# VIP1_Slice0_parser register map
Vendor: Texas Instruments
Peripheral module from a debugger description file (folder DRA75x_DRA74x).
Registers are 32-bit, read-only, reset 0x0 unless marked. A register's access mark holds for its fields unless they carry their own. Offsets are as the file gives them; lines under a group give offsets from that group; [hi:lo] are bit positions; {n}, {i} and the like mark numbered series; 'fields as' and 'values as' point back to an identical list; <NAME> marks a mode.

## VIP1_Slice0_parser
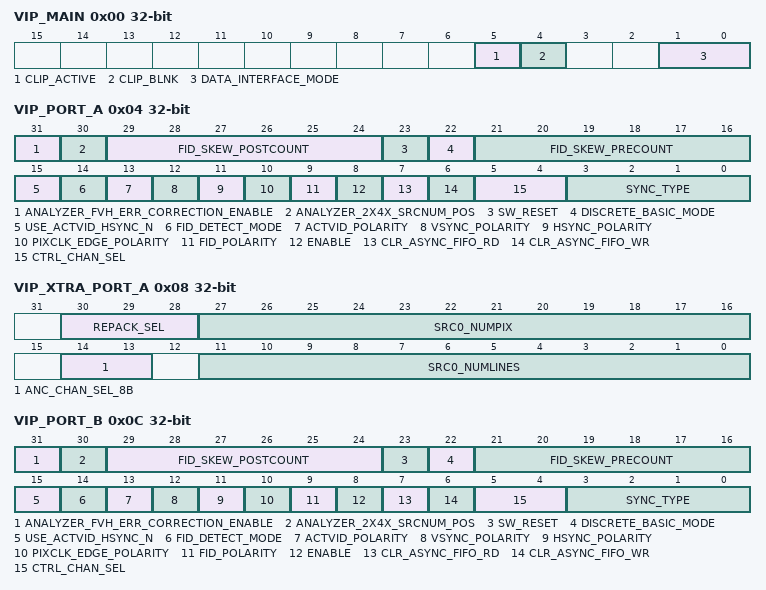
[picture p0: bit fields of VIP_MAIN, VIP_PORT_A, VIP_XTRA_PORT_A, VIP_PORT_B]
0x00 VIP_MAIN access per field — ain Configuration for VIP Parser
  [5] CLIP_ACTIVE rw — Discrete Sync Only 0 = Do not clip active pixels 1 = Clip Active Pixels as follows: 0xFF -andgt; 0xFE.. 0x00 -andgt; 0x01
  [4] CLIP_BLNK rw — Discrete Sync Only 0 = Do not clip Blanking Data 1 = Clip Blanking Data as follows: 0xFF -andgt; 0xFE.. 0x00 -andgt; 0x01
  [1:0] DATA_INTERFACE_MODE rw — 00 = 24b data interface. Uses Port A settings 01 = 16b data interface. Uses Port A settings. 10 = Dual independent 8b data interfaces. Uses independent Port A and Port B settings. 11 = Undefined
0x04 VIP_PORT_A rw — Configuration for Input Port A
  [31] ANALYZER_FVH_ERR_CORRECTION_ENABLE — Embedded Sync Only 0 = Ignore the protection bits in the XV (fvh) codeword header. This setting is typically desired. 1 = Use the protection bits in an attempt to do error correction for the fvh control bits.
  [30] ANALYZER_2X4X_SRCNUM_POS — Embedded Sync Only 0 = For 2x/4x mux mode, srcnum is in the least significant nibble of the XV/fvh codeword (srcnum replaces the protection bits) 1 = For 2x/4x mux mode, srcnum is in the least significant nibble of a horizontal blanking pixel value
  [29:24] FID_SKEW_POSTCOUNT — Discrete Sync Only post count value when using vsync skew in FID determination
  [23] SW_RESET — 0 = Normal 1 = Reset Port A logic. Must be set to ?0? again by the software for the module to function.
  [22] DISCRETE_BASIC_MODE — This register is valid for Discrete Sync mode only. 0 = Normal Discrete Mode. Hsync Style Capture operates as follows: - Captures line starting from HSYNC inactive to active condition. - VSYNC determined by sync window. - FID can be determined by VSYNC skew or captured from pin at first pixel in first line. ACTVID style capture works as follows: - Captures line during contiguous ACTVID envelope. - VSYNC is captured at the first pixel in each line. - FID is captured on first pixel of ACTVID window. 1 = Basic Discrete Mode. When using hsync with Hsync Style Capture operates as follows: - The last line of active video ends on the pixel clock cycle where VSYNC transitions from inactive to active. - FID pin value is captured on this cycle and is used for the next field. - FID detection by VSYNC skew is not allowed. ACTVID style capture works as follows: - VSYNC is expected to transition from inactive to active between ACTVID window. - This VSYNC transition allows the next line in an ACTVID envelope to be sent to a new VPDMA buffer. - FID value is determined by the FID pin value on the cycle where VSYNC transitions from inactive to active. In basic discrete mode, there is no Vertical Ancillary Data. Therefore, VPDMA descriptors should not use Ancillary Data channels.
  [21:16] FID_SKEW_PRECOUNT — Discrete Sync Only pre count value when using vsync skew in FID determination
  [15] USE_ACTVID_HSYNC_N — Discrete Sync Only 0 = Use HSYNC style line capture 1 = Use ACTVID style line capture
  [14] FID_DETECT_MODE — Discrete Sync Only 0 = Take FID from pin 1 = FID is determined by VSYNC skew
  [13] ACTVID_POLARITY — Discrete Sync Only 0 = ACTVID is active low 1 = ACTVID is active high
  [12] VSYNC_POLARITY — Discrete Sync Only 0 = VSYNC is active low 1 = VSYNC is active high
  [11] HSYNC_POLARITY — Discrete Sync Only 0 = HSYNC is active low 1 = HSYNC is active high
  [10] PIXCLK_EDGE_POLARITY — 0 = Rising Edge is active PIXCLK edge 1 = Falling Edge is active PIXCLK edge
  [9] FID_POLARITY — 0 = Keep FID as found 1 = Invert Determined Value of FID
  [8] ENABLE — 0 = Disable Port 1 = Enable Port
  [7] CLR_ASYNC_FIFO_RD — 0 = Normal 1 = Clear Async FIFO Read Logic
  [6] CLR_ASYNC_FIFO_WR — 0 = Normal 1 = Clear Async FIFO Write Logic
  [5:4] CTRL_CHAN_SEL — Embedded Sync Only In 8b mode.. there is only one channel on data[7:0]. In 16b mode.. there are two channels. The Luma Channel is on data[15:8]. The Chroma Channel is on data[7:0]. In 24b mode.. there are three channels. The R channel is on data[23:16].. the G channel is on [15:8]. and the B channel is on data[7:0]. 00 = Use data[7:0] to extract control codes. 01 = Use data[15:8] to extract control codes. 10 = Use data[23:16] to extract control codes. 11 = Undefined In 16b and 24b modes.. this register is also used to select the channel from which Ancillary Data is extracted. The Ancillary Data channel must be the same as the control code channel. For 8b mode.. the anc_chan_sel_8b register is used to select the Luma or Chroma channel from which Ancillary Data is taken.
  [3:0] SYNC_TYPE — 0000 = embedded sync single 4:2:2 YUV stream 0001 = embedded sync 2x multiplexed 4:2:2 YUV stream 0010 = embedded sync 4x multiplexed 4:2:2 YUV stream 0011 = embedded sync line multiplexed 4:2:2 YUV stream 0100 = discrete sync single 4:2:2 YUV stream 0101 = embedded sync single RGB stream or single 444 YUV stream 0110 = reserved 0111 = reserved 1000 = reserved 1001 = reserved 1010 = discrete sync single 24b RGB stream
0x08 VIP_XTRA_PORT_A access per field — ore Configuration for Input Port A
  [30:28] REPACK_SEL rw — 000 = Straight Through 001 = Cross Swap 010 = Left Center Swap 011 = Center Right Swap 100 = Right Rotate 101 = Left Rotate 110 = RAW16 to RGB565 Mapping 111 = RAW12 Swap
  [27:16] SRC0_NUMPIX rw — Number of expected pixels on Source Number 0. The Port_a_src0_size interrupt will trigger if a line is encountered that differs from this pixelcount.
  [14:13] ANC_CHAN_SEL_8B rw — In 8b mode, Vertically Ancillary Data typically resides in the Luma sites. This bit allows vertical ancillary data to be extracted from the chroma sites instead . 00 = Extract 8b Mode Vertical Ancillary Data from Luma Sites 01 = Extract 8b Mode Vertical Ancillary Data from Chroma Sites 10, 11 = Extract every single sample of vertical ancillary data. The output line is twice as wide as the other modes. For 16b and 24b inputs, ctrl_chan_sel is used to select which channel is used as a source for vertical ancillary data.
  [11:0] SRC0_NUMLINES rw — Number of expected lines on Source Number 0. The Port_a_src0_size interrupt will trigger if a field/frame is encountered that differs from this linecount.
0x0C VIP_PORT_B rw — Configuration for Input Port B
  [31] ANALYZER_FVH_ERR_CORRECTION_ENABLE — Embedded Sync Only 0 = Ignore the protection bits in the XV (fvh) codeword header. This setting is typically desired. 1 = Use the protection bits in an attempt to do error correction for the fvh control bits.
  [30] ANALYZER_2X4X_SRCNUM_POS — Embedded Sync Only 0 = For 2x/4x mux mode, srcnum is in the least significant nibble of the XV/fvh codeword (srcnum replaces the protection bits) 1 = For 2x/4x mux mode, srcnum is in the least significant nibble of a horizontal blanking pixel value
  [29:24] FID_SKEW_POSTCOUNT — Discrete Sync Only post count value when using vsync skew in FID determination
  [23] SW_RESET — 0 = Normal 1 = Reset Port B logic. Must be set to ?0? again by the software for the module to function.
  [22] DISCRETE_BASIC_MODE — This register is valid for Discrete Sync mode only. 0 = Normal Discrete Mode. Hsync Style Capture operates as follows: - Captures line starting from HSYNC inactive to active condition. - VSYNC determined by sync window. - FID can be determined by VSYNC skew or captured from pin at first pixel in first line. ACTVID style capture works as follows: - Captures line during contiguous ACTVID envelope. - VSYNC is captured at the first pixel in each line. - FID is captured on first pixel of ACTVID window. 1 = Basic Discrete Mode. When using hsync with Hsync Style Capture operates as follows: - The last line of active video ends on the pixel clock cycle where VSYNC transitions from inactive to active. - FID pin value is captured on this cycle and is used for the next field. - FID detection by VSYNC skew is not allowed. ACTVID style capture works as follows: - VSYNC is expected to transition from inactive to active between ACTVID window. - This VSYNC transition allows the next line in an ACTVID envelope to be sent to a new VPDMA buffer. - FID value is determined by the FID pin value on the cycle where VSYNC transitions from inactive to active. In basic discrete mode, there is no Vertical Ancillary Data. Therefore, VPDMA descriptors should not use Ancillary Data channels.
  [21:16] FID_SKEW_PRECOUNT — Discrete Sync Only pre count value when using vsync skew in FID determination
  [15] USE_ACTVID_HSYNC_N — Discrete Sync Only 0 = Use HSYNC style line capture 1 = Use ACTVID style line capture
  [14] FID_DETECT_MODE — Discrete Sync Only 0 = Take FID from pin 1 = FID is determined by VSYNC skew
  [13] ACTVID_POLARITY — Discrete Sync Only 0 = ACTVID is active low 1 = ACTVID is active high
  [12] VSYNC_POLARITY — Discrete Sync Only 0 = VSYNC is active low 1 = VSYNC is active high
  [11] HSYNC_POLARITY — Discrete Sync Only 0 = HSYNC is active low 1 = HSYNC is active high
  [10] PIXCLK_EDGE_POLARITY — 0 = Rising Edge is active PIXCLK edge 1 = Falling Edge is active PIXCLK edge
  [9] FID_POLARITY — 0 = Keep FID as found 1 = Invert Determined Value of FID
  [8] ENABLE — 0 = Disable 1 = Enable
  [7] CLR_ASYNC_FIFO_RD — 0 = Normal 1 = Clear Async FIFO Read Logic
  [6] CLR_ASYNC_FIFO_WR — 0 = Normal 1 = Clear Async FIFO Write Logic
  [5:4] CTRL_CHAN_SEL — PORT B supports on 8b mode. Always write 0 to this field. The anc_chan_sel_8b register is used to select the Luma or Chroma channel from which Ancillary Data is taken.
  [3:0] SYNC_TYPE — 0000 = embedded sync single YUV stream 0001 = embedded sync 2x multiplexed YUV stream 0010 = embedded sync 4x multiplexed YUV stream 0011 = embedded sync line multiplexed YUV stream 0100 = discrete sync single YUV stream 0101 = embedded sync single RGB stream 0110 = reserved 0111 = reserved 1000 = reserved 1001 = reserved 1010 = discrete sync single 24b RGB stream
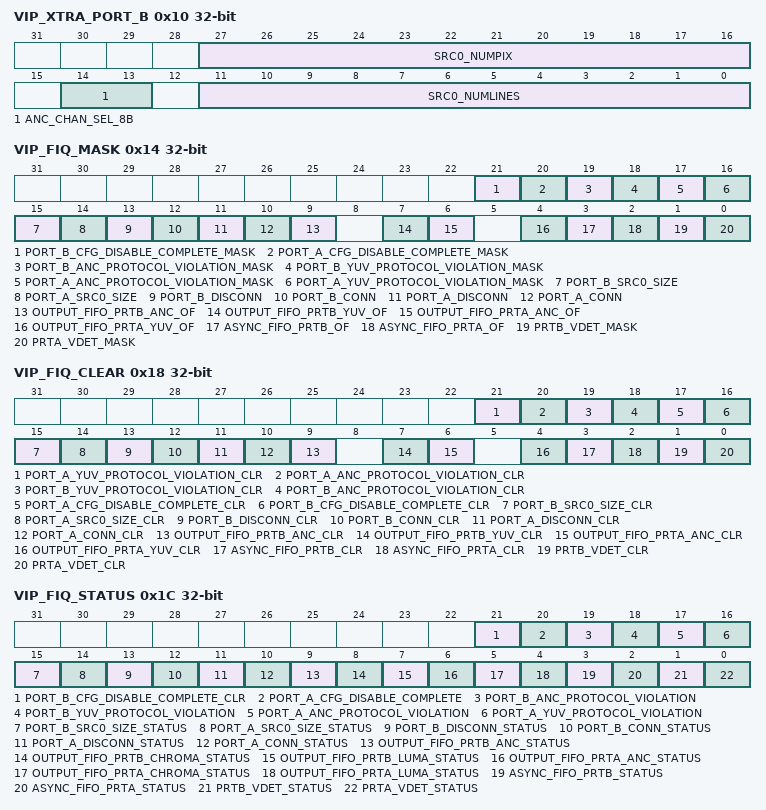
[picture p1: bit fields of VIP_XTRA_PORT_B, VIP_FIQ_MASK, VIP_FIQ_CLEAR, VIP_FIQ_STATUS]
0x10 VIP_XTRA_PORT_B access per field — ore Configuration for Input Port B
  [27:16] SRC0_NUMPIX rw — Number of expected pixels on Source Number 0. The Port_b_src0_size interrupt will trigger if a line is encountered that differs from this pixelcount.
  [14:13] ANC_CHAN_SEL_8B rw — In 8b mode, Vertically Ancillary Data typically resides in the Luma sites. This bit allows vertical ancillary data to be extracted from the chroma sites instead . 00 = Extract 8b Mode Vertical Ancillary Data from Luma Sites 01 = Extract 8b Mode Vertical Ancillary Data from Chroma Sites 10, 11 = Extract every single sample of vertical ancillary data. The output line is twice as wide as the other modes. For 16b and 24b inputs, ctrl_chan_sel is used to select which channel is used as a source for vertical ancillary data.
  [11:0] SRC0_NUMLINES rw — Number of expected lines on Source Number 0. The Port_b_src0_size interrupt will trigger if a field/frame is encountered that differs from this linecount.
0x14 VIP_FIQ_MASK access per field — ask Bits for ARM FIQs
  [21] PORT_B_CFG_DISABLE_COMPLETE_MASK rw
  [20] PORT_A_CFG_DISABLE_COMPLETE_MASK rw
  [19] PORT_B_ANC_PROTOCOL_VIOLATION_MASK rw — Port B ANC VPI Protocol Violation Mask
  [18] PORT_B_YUV_PROTOCOL_VIOLATION_MASK rw — Port B YUV VPI Protocol Violation Mask
  [17] PORT_A_ANC_PROTOCOL_VIOLATION_MASK rw — Port A ANC VPI Protocol Violation Mask
  [16] PORT_A_YUV_PROTOCOL_VIOLATION_MASK rw — Port A YUV VPI Protocol Violation Mask
  [15] PORT_B_SRC0_SIZE rw — Video size detected on Port B does not match size programmed in xtra_port_b register
  [14] PORT_A_SRC0_SIZE rw — Video size detected on Port A does not match size programmed in xtra_port_a register
  [13] PORT_B_DISCONN rw — Port B Link Disconnect Srcnum 0 Mask
  [12] PORT_B_CONN rw — Port B Link Connect Srcnum 0 Mask
  [11] PORT_A_DISCONN rw — Port A Link Disconnect Scrnum 0 Mask
  [10] PORT_A_CONN rw — Port A Link Connect Srcnum 0 Mask
  [9] OUTPUT_FIFO_PRTB_ANC_OF rw — Output FIFO Port B Ancillary Overflow Mask
  [7] OUTPUT_FIFO_PRTB_YUV_OF rw — Output FIFO Port B Luma Overflow Mask
  [6] OUTPUT_FIFO_PRTA_ANC_OF rw — Output FIFO Port A Ancillary Overflow Mask
  [4] OUTPUT_FIFO_PRTA_YUV_OF rw — Output FIFO Port A Luma Overflow Mask
  [3] ASYNC_FIFO_PRTB_OF rw — Port B Async FIFO Overflow FIQ Mask
  [2] ASYNC_FIFO_PRTA_OF rw — Port A Async FIFO Overflow FIQ Mask
  [1] PRTB_VDET_MASK rw — Port B Video Detect FIQ Mask
  [0] PRTA_VDET_MASK rw — Port A Video Detect FIQ Mask
0x18 VIP_FIQ_CLEAR access per field — Clears bits in the FIQ Status
  [21] PORT_A_YUV_PROTOCOL_VIOLATION_CLR rw — Write 1 followed by 0 to Clear Port B Cfg Disable Complete FIQ
  [20] PORT_A_ANC_PROTOCOL_VIOLATION_CLR rw — Write 1 followed by 0 to Clear Port A Cfg Disable Complete FIQ
  [19] PORT_B_YUV_PROTOCOL_VIOLATION_CLR rw — Write 1 followed by 0 to Clear Port B ANC VPI Protocol Violation FIQ
  [18] PORT_B_ANC_PROTOCOL_VIOLATION_CLR rw — Write 1 followed by 0 to Clear Port B YUV VPI Protocol Violation FIQ
  [17] PORT_A_CFG_DISABLE_COMPLETE_CLR rw — Write 1 followed by 0 to Clear Port A ANC VPI Protocol Violation FIQ
  [16] PORT_B_CFG_DISABLE_COMPLETE_CLR rw — Write 1 followed by 0 to Clear Port A YUV VPI Protocol Violation FIQ
  [15] PORT_B_SRC0_SIZE_CLR rw — Write 1 followed by 0 to Clear Port B Src0 Size FIQ
  [14] PORT_A_SRC0_SIZE_CLR rw — Write 1 followed by 0 to Clear Port A Src0 Size FIQ
  [13] PORT_B_DISCONN_CLR rw — Write 1 followed by 0 to Clear Port B Link Disconnect FIQ
  [12] PORT_B_CONN_CLR rw — Write 1 followed by 0 to Clear Port B Link Connect FIQ
  [11] PORT_A_DISCONN_CLR rw — Write 1 followed by 0 to Clear Port A Link Disconnect FIQ
  [10] PORT_A_CONN_CLR rw — Write 1 followed by 0 to Clear Port A Link Connect FIQ
  [9] OUTPUT_FIFO_PRTB_ANC_CLR rw — Write 1 followed by 0 to Clear Output FIFO Port B Ancillary Overflow FIQ
  [7] OUTPUT_FIFO_PRTB_YUV_CLR rw — Write 1 followed by 0 to Clear Output FIFO Port B Luma Overflow FIQ
  [6] OUTPUT_FIFO_PRTA_ANC_CLR rw — Write 1 followed by 0 to Clear Output FIFO Port A Ancillary Overflow FIQ
  [4] OUTPUT_FIFO_PRTA_YUV_CLR rw — Write 1 followed by 0 to Clear Output FIFO Port A Luma Overflow FIQ
  [3] ASYNC_FIFO_PRTB_CLR rw — Write 1 followed by 0 to Clear Async FIFO Port B Overflow FIQ
  [2] ASYNC_FIFO_PRTA_CLR rw — Write 1 followed by 0 to Clear Async FIFO Port A Overflow FIQ
  [1] PRTB_VDET_CLR rw — Write 1 followed by 0 to Clear Video Detect FIQ for Port B
  [0] PRTA_VDET_CLR rw — Write 1 followed by 0 to Clear Video Detect FIQ for Port A
0x1C VIP_FIQ_STATUS — FIQ Status values
  [21] PORT_B_CFG_DISABLE_COMPLETE_CLR — Port B Cfg Disable Complete FIQ
  [20] PORT_A_CFG_DISABLE_COMPLETE — Port A Cfg Disable Complete FIQ
  [19] PORT_B_ANC_PROTOCOL_VIOLATION — Port B ANC VPI Protocol Violation FIQ
  [18] PORT_B_YUV_PROTOCOL_VIOLATION — Port B YUV VPI Protocol Violation FIQ
  [17] PORT_A_ANC_PROTOCOL_VIOLATION — Port A ANC VPI Protocol Violation FIQ
  [16] PORT_A_YUV_PROTOCOL_VIOLATION — Port A YUV VPI Protocol Violation FIQ
  [15] PORT_B_SRC0_SIZE_STATUS — Port B Source 0 Size FIQ
  [14] PORT_A_SRC0_SIZE_STATUS — Port A Source 0 Size FIQ
  [13] PORT_B_DISCONN_STATUS — Port B Disconnect FIQ
  [12] PORT_B_CONN_STATUS — Port B Connect FIQ
  [11] PORT_A_DISCONN_STATUS — Port A Disconnect FIQ
  [10] PORT_A_CONN_STATUS — Port A Connect FIQ
  [9] OUTPUT_FIFO_PRTB_ANC_STATUS — Output FIFO Port B Ancillary Overflow Status
  [8] OUTPUT_FIFO_PRTB_CHROMA_STATUS — Output FIFO Port B Chroma Overflow Status
  [7] OUTPUT_FIFO_PRTB_LUMA_STATUS — Output FIFO Port B Luma Overflow Status
  [6] OUTPUT_FIFO_PRTA_ANC_STATUS — Output FIFO Port A Ancillary Overflow Status
  [5] OUTPUT_FIFO_PRTA_CHROMA_STATUS — Output FIFO Port A Chroma Overflow Status
  [4] OUTPUT_FIFO_PRTA_LUMA_STATUS — Output FIFO Port A Luma Overflow Status
  [3] ASYNC_FIFO_PRTB_STATUS — Async FIFO Port B Overflow Status
  [2] ASYNC_FIFO_PRTA_STATUS — Async FIFO Port A Overflow Status
  [1] PRTB_VDET_STATUS — VDET Status for Port B
  [0] PRTA_VDET_STATUS — VDET Status for Port A
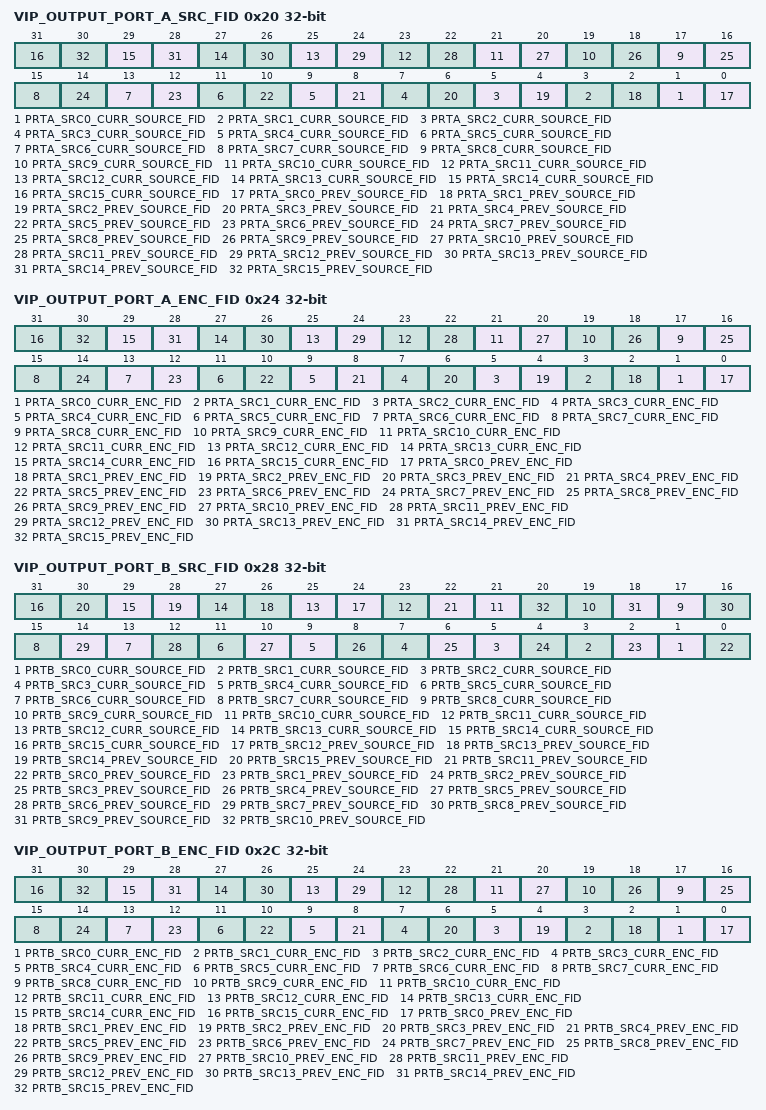
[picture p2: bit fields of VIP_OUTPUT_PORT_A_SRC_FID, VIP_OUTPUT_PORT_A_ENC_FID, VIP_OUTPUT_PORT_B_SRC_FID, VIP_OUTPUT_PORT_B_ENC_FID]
0x20 VIP_OUTPUT_PORT_A_SRC_FID — Current and Previous Output Port A Source FID values
  [2n+1] PRTA_SRC{n}_CURR_SOURCE_FID (n=0..15) — For Source ID {n} from Port A. Source Field ID for Current Field
  [2n] PRTA_SRC{n}_PREV_SOURCE_FID (n=0..15) — For Source ID {n} from Port A. Source Field ID for Previous Field
0x24 VIP_OUTPUT_PORT_A_ENC_FID — Current and Previous Output Port A Encoder FID values
  [2n+1] PRTA_SRC{n}_CURR_ENC_FID (n=0..15) — For Source ID {n} from Port A. Encoder Field ID for Current Field
  [2n] PRTA_SRC{n}_PREV_ENC_FID (n=0..15) — For Source ID {n} from Port A. Encoder Field ID for Previous Field
0x28 VIP_OUTPUT_PORT_B_SRC_FID — Current and Previous Output Port B Source FID values
  [2n+1] PRTB_SRC{n}_CURR_SOURCE_FID (n=0..15) — For Source ID {n} from Port B. Source Field ID for Current Field
  [2n] PRTB_SRC{n}_PREV_SOURCE_FID (n=12..15) — For Source ID {n} from Port B. Source Field ID for Previous Field
  [22] PRTB_SRC11_PREV_SOURCE_FID — For Source ID 11. from Port B Source Field ID for Previous Field
  [2n] PRTB_SRC{n}_PREV_SOURCE_FID (n=0..10) — For Source ID {n} from Port B. Source Field ID for Previous Field
0x2C VIP_OUTPUT_PORT_B_ENC_FID — Current and Previous Output Port B Encoder FID values
  [2n+1] PRTB_SRC{n}_CURR_ENC_FID (n=0..15) — For Source ID {n} from Port B. Encoder Field ID for Current Field
  [2n] PRTB_SRC{n}_PREV_ENC_FID (n=0..15) — For Source ID {n} from Port B. Encoder Field ID for Previous Field
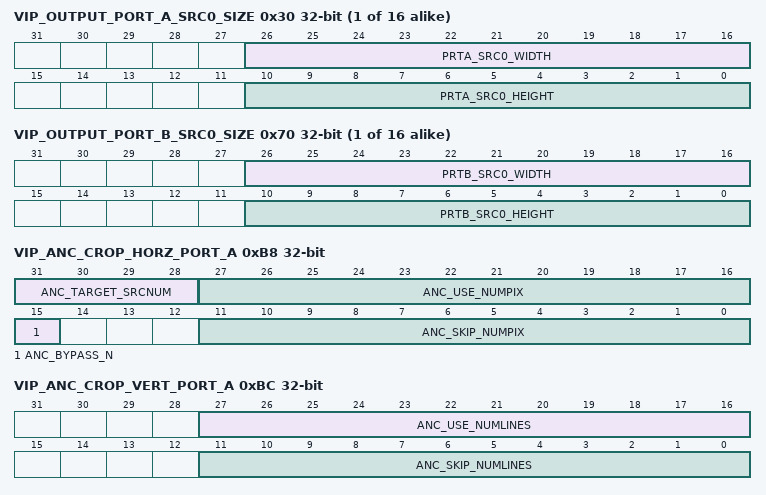
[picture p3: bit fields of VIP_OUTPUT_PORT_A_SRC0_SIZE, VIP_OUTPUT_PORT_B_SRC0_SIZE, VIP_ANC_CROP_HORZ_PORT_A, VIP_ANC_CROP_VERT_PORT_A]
{0x30+4i} VIP_OUTPUT_PORT_A_SRC{i}_SIZE (i=0..15) — Width and Height for Source {i}
  [26:16] PRTA_SRC{i}_WIDTH — On Port A. Width of Source ID {i}
  [10:0] PRTA_SRC{i}_HEIGHT — On Port A. Height of Source ID {i}
{0x70+4i} VIP_OUTPUT_PORT_B_SRC{i}_SIZE (i=0..15) — Width and Height for Source {i}
  [26:16] PRTB_SRC{i}_WIDTH — On Port B. Width of Source ID {i}
  [10:0] PRTB_SRC{i}_HEIGHT — On Port B. Height of Source ID {i}
0xB0 VIP_PORT_A_VDET_VEC — Each bit represents the VDET bit setting for Line Mux Mode
  [31:0] PRTA_VDET_VEC — For Embedded Sync Only In Line Mux Mode. each bit represents the vdet value on Port A for the corresponding source id. This vector is meaningless for 1x/2x/4x mux modes.
0xB4 VIP_PORT_B_VDET_VEC — Each bit represents the VDET bit setting for Line Mux Mode
  [31:0] PRTB_VDET_VEC — For Embedded Sync Only In Line Mux Mode. each bit represents the vdet value on Port B for the corresponding source id. This vector is meaningless for 1x/2x/4x mux modes.
0xB8 VIP_ANC_CROP_HORZ_PORT_A access per field — Ancillary Cropping Configuration for Input Port A
  [31:28] ANC_TARGET_SRCNUM rw — The cropping module can work on only one srcnum. specified in this field. for each dss_vip_parser output port (Ancillary data).
  [27:16] ANC_USE_NUMPIX rw — When cropping, the number of pixels to keep after the skip_numpix value. skip_numpix + use_numpix must be smaller than the original line width.
  [15] ANC_BYPASS_N rw — 0 = Bypass cropping module 1 = Cropping module enabled
  [11:0] ANC_SKIP_NUMPIX rw — The number of pixels to crop from the beginning of each line.
0xBC VIP_ANC_CROP_VERT_PORT_A access per field — Ancillary Cropping Configuration for Input Port A
  [27:16] ANC_USE_NUMLINES rw — When cropping, the number of lines to keep after the skip_numlines value. Use_numlines + skip_numlines must be smaller than the total number of lines in the srcnum's ancillary data region.
  [11:0] ANC_SKIP_NUMLINES rw — The number of lines to crop from the top of the vertical ancillary data region.
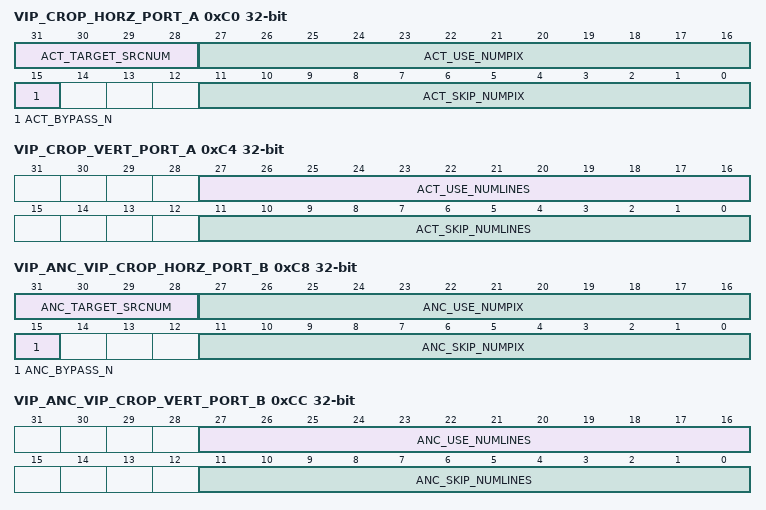
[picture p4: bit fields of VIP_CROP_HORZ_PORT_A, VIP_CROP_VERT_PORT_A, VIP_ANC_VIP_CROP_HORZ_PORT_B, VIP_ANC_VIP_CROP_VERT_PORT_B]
0xC0 VIP_CROP_HORZ_PORT_A access per field — Active Video Cropping Configuration for Input Port A
  [31:28] ACT_TARGET_SRCNUM rw — The cropping module can work on only one srcnum. specified in this field. for each dss_vip_parser output port (Active video).
  [27:16] ACT_USE_NUMPIX rw — When cropping, the number of pixels to keep after the skip_numpix value. skip_numpix + use_numpix must be smaller than the original line width.
  [15] ACT_BYPASS_N rw — 0 = Bypass cropping module 1 = Cropping module enabled
  [11:0] ACT_SKIP_NUMPIX rw — The number of pixels to crop from the beginning of each line.
0xC4 VIP_CROP_VERT_PORT_A access per field — Active Video Cropping Configuration for Input Port A
  [27:16] ACT_USE_NUMLINES rw — When cropping.. the number of lines to keep after the skip_numlines value. Use_numlines + skip_numlines must be smaller than the total number of lines in the srcnum's active video region.
  [11:0] ACT_SKIP_NUMLINES rw — The number of lines to crop from the top of the vertical active video region.
0xC8 VIP_ANC_VIP_CROP_HORZ_PORT_B access per field — Ancillary Cropping Configuration for Input Port B
  fields as VIP_ANC_CROP_HORZ_PORT_A
0xCC VIP_ANC_VIP_CROP_VERT_PORT_B access per field — Ancillary Cropping Configuration for Input Port B
  [27:16] ANC_USE_NUMLINES rw — When cropping, the number of lines to keep after the skip_numlines value. Use_numlines + skip_numlines must be smaller than the total number of lines in the srcnums active video region.
  [11:0] ANC_SKIP_NUMLINES rw — The number of lines to crop from the top of the vertical ancillary data region.
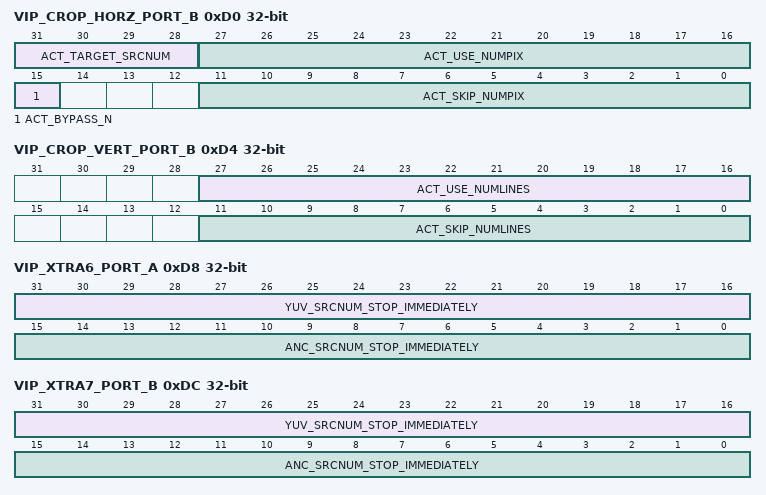
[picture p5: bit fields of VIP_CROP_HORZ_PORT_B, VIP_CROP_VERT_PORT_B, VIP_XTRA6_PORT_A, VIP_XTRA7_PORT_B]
0xD0 VIP_CROP_HORZ_PORT_B access per field — Active Video Cropping Configuration for Input Port B
  fields as VIP_CROP_HORZ_PORT_A
0xD4 VIP_CROP_VERT_PORT_B access per field — Active Video Cropping Configuration for Input Port B
  [27:16] ACT_USE_NUMLINES rw — When cropping, the number of lines to keep after the skip_numlines value. Use_numlines + skip_numlines must be smaller than the total number of lines in the srcnum's active video region.
  [11:0] ACT_SKIP_NUMLINES rw — The number of lines to crop from the top of the vertical active video region.
0xD8 VIP_XTRA6_PORT_A rw — Cfg Disable Active Srcnum Vector Input for Port A
  [31:16] YUV_SRCNUM_STOP_IMMEDIATELY — For the Active Video Port to the VPDMA, logic exists to ensure that a complete frame is sent out to the VPDMA following cfg_enable transitioning inactive for that port. Each bit in this vector represents a srcnum (remapped srcnum for TI line mux mode) going to the VPDMA. For example, bit 0 is srcnum 0, bit 1 is srcnum 1, etc. A ?0? in a bit position means that the hardware will wait for that srcnum, if it is in the middle of a frame, to continue until the end of the frame before stopping. A ?1? in a bit position means that it is ok for a srcnum to stop in the middle of a frame. For example, suppose a source is removed and the input will never complete sending a frame. If the bit position representing that srcnum is set to ?0?, the port will never disable.
  [15:0] ANC_SRCNUM_STOP_IMMEDIATELY — For the Ancillary Data Port to the VPDMA, logic exists to ensure that a complete frame is sent out to the VPDMA following cfg_enable transitioning inactive for that port. Each bit in this vector represents a srcnum (remapped srcnum for TI line mux mode) going to the VPDMA. For example, bit 0 is srcnum 0, bit 1 is srcnum 1, etc. A ?0? in a bit position means that the hardware will wait for that srcnum, if it is in the middle of a frame, to continue until the end of the frame before stopping. A ?1? in a bit position means that it is ok for a srcnum to stop in the middle of a frame. For example, suppose a source is removed and the input will never complete sending a frame. If the bit position representing that srcnum is set to ?0?, the port will never disable.
0xDC VIP_XTRA7_PORT_B rw — Cfg Disable Active Srcnum Vector Input for Port B
  fields as VIP_XTRA6_PORT_A
0xE0 VIP_XTRA8_PORT_A rw — Reserved Register for Port A
  [31:0] RESERVED — ust be 0x0 at all times.
0xE4 VIP_XTRA9_PORT_B rw — Reserved Register for Port B
  [31:0] RESERVED — ust be 0x0 at all times.
